AUTOSAR XML (schema 4-0-3)
standard types defined: Boolean, UInt8
package /AUTOSAR_Platform/DataConstrs
  range DC_Boolean: raw 0..1
package /PATAC/Facility/DataTypes/Implementation
  unit NoUnit: factor-si-to-unit=1, offset-si-to-unit=0
package /PATAC/MSM/ComponentTypes
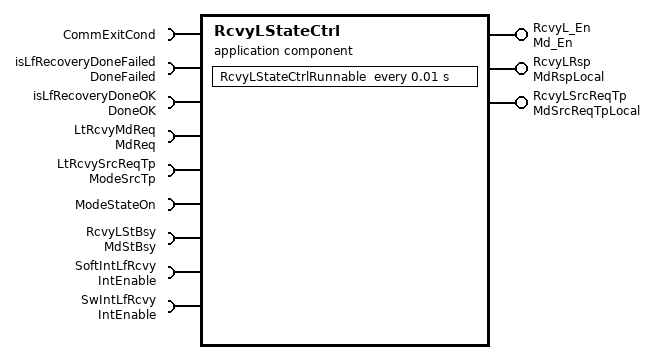
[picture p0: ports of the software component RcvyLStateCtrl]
  application sw component type RcvyLStateCtrl
    provide port RcvyL_En: nonqueued-sender-com-spec{data-element=Md_En/Val, init-value=0}, provided-interface=Md_En
    provide port RcvyLRsp: nonqueued-sender-com-spec{data-element=MdRspLocal/Val, init-value=0}, provided-interface=MdRspLocal
    provide port RcvyLSrcReqTp: nonqueued-sender-com-spec{data-element=MdSrcReqTpLocal/Val, init-value=0}, provided-interface=MdSrcReqTpLocal
    9 x require port:
      CommExitCond: nonqueued-receiver-com-spec{data-element=CommExitCond/Val, filter=data-filter-type=ALWAYS, init-value=0}, required-interface=CommExitCond
      isLfRecoveryDoneFailed: nonqueued-receiver-com-spec{data-element=DoneFailed/Val, filter=data-filter-type=ALWAYS, init-value=0}, required-interface=DoneFailed
      isLfRecoveryDoneOK: nonqueued-receiver-com-spec{data-element=DoneOK/Val, filter=data-filter-type=ALWAYS, init-value=0}, required-interface=DoneOK
      LtRcvyMdReq: nonqueued-receiver-com-spec{data-element=MdReq/Val, filter=data-filter-type=ALWAYS, init-value=0}, required-interface=MdReq
      LtRcvySrcReqTp: nonqueued-receiver-com-spec{data-element=ModeSrcTp/Val, filter=data-filter-type=ALWAYS, init-value=0}, required-interface=ModeSrcTp
      ModeStateOn: nonqueued-receiver-com-spec{data-element=ModeStateOn/Val, filter=data-filter-type=ALWAYS, init-value=0}, required-interface=ModeStateOn
      RcvyLStBsy: nonqueued-receiver-com-spec{data-element=MdStBsy/Val, filter=data-filter-type=ALWAYS, init-value=0}, required-interface=MdStBsy
      SoftIntLfRcvy: nonqueued-receiver-com-spec{data-element=IntEnable/Val, filter=data-filter-type=ALWAYS, init-value=0}, required-interface=IntEnable
      SwIntLfRcvy: nonqueued-receiver-com-spec{data-element=IntEnable/Val, filter=data-filter-type=ALWAYS, init-value=0}, required-interface=IntEnable
    behavior RcvyLStateCtrl_InternalBehavior
      timing event TMT_EZEStateCtrlRunnable: start-on-event=RcvyLStateCtrlRunnable, period=0.01
      runnable RcvyLStateCtrlRunnable
        data-receive-point-by-arguments:
          9 x access:
            REC_CommExitCond_Val: accessed-variable=CommExitCond.Val
            REC_EZEStBsy_Val: accessed-variable=RcvyLStBsy.Val
            REC_isLfRecoveryDoneFailed_Val: accessed-variable=isLfRecoveryDoneFailed.Val
            REC_isLfRecoveryDoneOK_Val: accessed-variable=isLfRecoveryDoneOK.Val
            REC_LtRcvyMdReq_Val: accessed-variable=LtRcvyMdReq.Val
            REC_LtRcvySrcReqTp_Val: accessed-variable=LtRcvySrcReqTp.Val
            REC_ModeStateOn_Val: accessed-variable=ModeStateOn.Val
            REC_SoftIntLfRcvy_Val: accessed-variable=SoftIntLfRcvy.Val
            REC_SwIntLfRcvy_Val: accessed-variable=SwIntLfRcvy.Val
        data-send-points:
          access SEND_EZQ_En_Val: accessed-variable=RcvyL_En.Val
          access SEND_EZQRsp_Val: accessed-variable=RcvyLRsp.Val
          access SEND_EZQSrcReqTp_Val: accessed-variable=RcvyLSrcReqTp.Val
  swc implementation RcvyLStateCtrl_Implementation: behavior=RcvyLStateCtrl_InternalBehavior
    code-descriptors:
      code Default: artifact-descriptors=autosar-engineering-object={short-label=Default, category=SWSRC}
package /PATAC/MSM/DataTypes/ImplementationDataTypes
  impl type IntEnable: category=VALUE, base-type=Boolean, sw-calibration-access=READ-ONLY, type-emitter=RTE
package /PATAC/MSM/ModeAdjust/DataType
  impl type MdRspLocal1: category=VALUE, base-type=UInt8, sw-calibration-access=READ-ONLY, compu {0=MdRsp_None, 1=MdRsp_RecallSuccessfully, 2=MdRsp_RecallUnsuccessfully_LocalInterrupt, 3=MdRsp_RecallUnsuccessfully_Error, 4=MdRsp_RecallOngoing, 5=MdRsp_RecallHalt}, type-emitter=RTE
  impl type SrcReqTp1: category=VALUE, base-type=UInt8, sw-calibration-access=READ-ONLY, compu {0=SrcReqTp_None, 1=SrcReqTp_Local, 2=SrcReqTp_HMI2L, 3=SrcReqTp_HMI2R, 4=SrcReqTp_HMI, 5=SrcReqTp_Remote, 6=SrcReqTp_SRS}, type-emitter=RTE
package /PATAC/MSM/ModeAdjust/PortInterface
  11 x sender receiver interface:
    CommExitCond: invalidation-policy{data-element=CommExitCond/Val, handle-invalid=DONT-INVALIDATE}
      data Val: type=Boolean
    DoneFailed: invalidation-policy{data-element=DoneFailed/Val, handle-invalid=DONT-INVALIDATE}
      data Val: type=Boolean
    DoneOK: invalidation-policy{data-element=DoneOK/Val, handle-invalid=DONT-INVALIDATE}
      data Val: type=Boolean
    IntEnable: invalidation-policy{data-element=IntEnable/Val, handle-invalid=DONT-INVALIDATE}
      data Val: type=IntEnable
    Md_En: invalidation-policy{data-element=Md_En/Val, handle-invalid=DONT-INVALIDATE}
      data Val: type=Boolean
    MdReq: invalidation-policy{data-element=MdReq/Val, handle-invalid=DONT-INVALIDATE}
      data Val: type=Boolean
    MdRspLocal: invalidation-policy{data-element=MdRspLocal/Val, handle-invalid=DONT-INVALIDATE}
      data Val: type=MdRspLocal1
    MdSrcReqTpLocal: invalidation-policy{data-element=MdSrcReqTpLocal/Val, handle-invalid=DONT-INVALIDATE}
      data Val: type=SrcReqTp1
    MdStBsy: invalidation-policy{data-element=MdStBsy/Val, handle-invalid=DONT-INVALIDATE}
      data Val: type=Boolean
    ModeSrcTp: invalidation-policy{data-element=ModeSrcTp/Val, handle-invalid=DONT-INVALIDATE}
      data Val: type=SrcReqTp1
    ModeStateOn: invalidation-policy{data-element=ModeStateOn/Val, handle-invalid=DONT-INVALIDATE}
      data Val: type=Boolean
